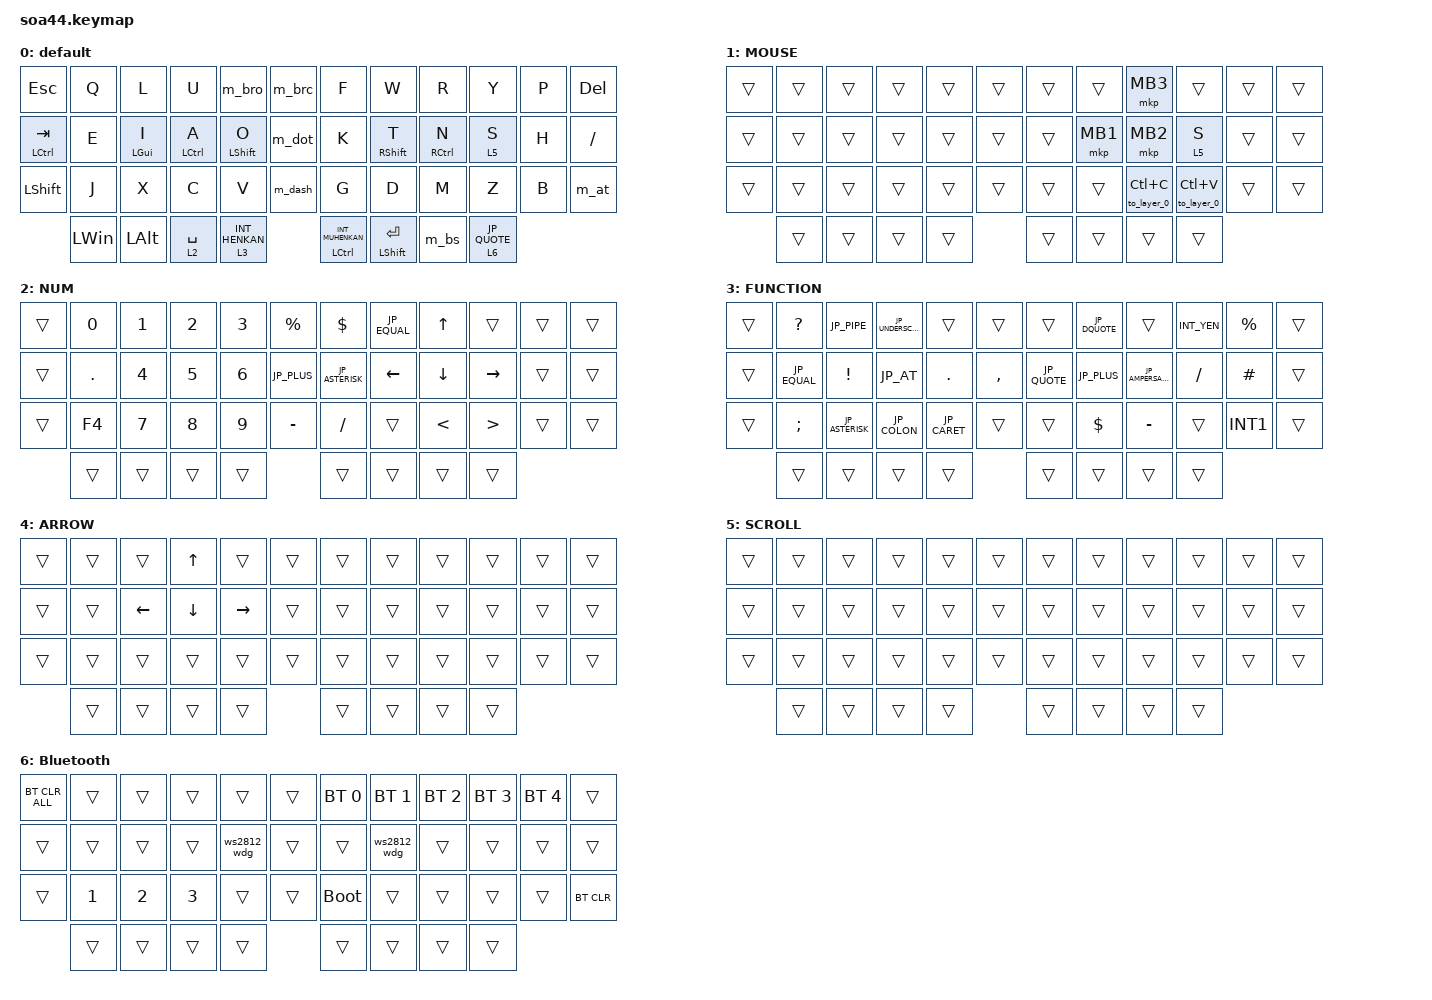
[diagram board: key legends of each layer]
#include <behaviors.dtsi>
#include <dt-bindings/zmk/bt.h>
#include <dt-bindings/zmk/keys.h>
#include <dt-bindings/zmk/pointing.h>
#include <input/processors.dtsi>
#include <behaviors/ws2812_widget.dtsi>

&mkp_input_listener {
    input-processors = <&zip_temp_layer 1 250>;
};
// OS設定を日本語キーボードのまま使用するための変換定義

#define JP_DQUOTE       AT                // "
#define JP_AMPERSAND    CARET             // &
#define JP_QUOTE        AMPERSAND         // '
#define JP_EQUAL        UNDER             // =
#define JP_CARET        EQUAL             // ^
#define JP_YEN          0x89              // ¥
#define JP_PLUS         COLON             // +
#define JP_TILDE        PLUS              // ~
#define JP_PIPE         LS(0x89)          // |
#define JP_AT           LEFT_BRACKET      // @
#define JP_COLON        SINGLE_QUOTE      // :
#define JP_ASTERISK     DOUBLE_QUOTES     // *
#define JP_BACKQUOTE    LEFT_BRACE        // `
#define JP_UNDERSCORE   LS(0x87)          // _
#define JP_LBRACKET     RIGHT_BRACKET     // [
#define JP_RBRACKET     BACKSLASH         // ]
#define JP_LPAREN       ASTERISK          // (
#define JP_RPAREN       LEFT_PARENTHESIS  // )
#define JP_LBRACE       RIGHT_BRACE       // {
#define JP_RBRACE       PIPE              // }
#define JP_KANA         LANGUAGE_1        // かな
#define JP_EISU         LANGUAGE_2        // 英数
#define JP_HANZEN       GRAVE             // 半角/全角

&mt {
    flavor = "balanced";
    quick-tap-ms = <0>;
};

/ {
    combos {
        compatible = "zmk,combos";

        shift_ctrl {
            bindings = <&kp LS(LCTRL)>;
            key-positions = <12 13>;
        };
    };

    macros {
        to_layer_0: to_layer_0 {
            compatible = "zmk,behavior-macro-one-param";
            #binding-cells = <1>;
            bindings = <&to 0 &macro_param_1to1 &kp MACRO_PLACEHOLDER>;
            label = "TO_LAYER_0";
        };
    };

    behaviors {
        lt_to_layer_0: lt_to_layer_0 {
            compatible = "zmk,behavior-hold-tap";
            label = "LAYER_TAP_TO_0";
            bindings = <&mo>, <&to_layer_0>;
            #binding-cells = <2>;
            tapping-term-ms = <200>;
        };
         // root：Shiftで分岐
        m_bro: m_bro {
            compatible = "zmk,behavior-mod-morph";
            #binding-cells = <0>;
            bindings = <&m_bron>, <&m_bros>;
            mods = <(MOD_LSFT|MOD_RSFT)>;
        };

        // 非Shiftルート：Ctrl判定
        m_bron: m_bron {
            compatible = "zmk,behavior-mod-morph";
            #binding-cells = <0>;
            bindings = <&kp JP_LPAREN>, <&kp JP_LBRACE>; // ( , {
            mods = <(MOD_LCTL|MOD_RCTL)>;
        };

        // Shiftルート：Ctrl判定
        m_bros: m_bros {
            compatible = "zmk,behavior-mod-morph";
            #binding-cells = <0>;
            bindings = <&kp JP_LBRACKET>, <&kp LT>; // [ , <
            mods = <(MOD_LCTL|MOD_RCTL)>;
        };
       // root：Shiftで分岐
        m_brc: m_brc {
            compatible = "zmk,behavior-mod-morph";
            #binding-cells = <0>;
            bindings = <&m_brcn>, <&m_brcs>;
            mods = <(MOD_LSFT|MOD_RSFT)>;
        };

        // 非Shiftルート：Ctrl判定
        m_brcn: m_brcn {
            compatible = "zmk,behavior-mod-morph";
            #binding-cells = <0>;
            bindings = <&kp JP_RPAREN>, <&kp JP_RBRACE>; // ) , }
            mods = <(MOD_LCTL|MOD_RCTL)>;
        };

        // Shiftルート：Ctrl判定
        m_brcs: m_brcs {
            compatible = "zmk,behavior-mod-morph";
            #binding-cells = <0>;
            bindings = <&kp JP_RBRACKET>, <&kp GT>; // ] , >
            mods = <(MOD_LCTL|MOD_RCTL)>;
        };
        m_dot: m_dot {
            compatible = "zmk,behavior-mod-morph";
            #binding-cells = <0>;
            bindings = <&kp PERIOD>, <&kp COMMA>; // . , ,
            mods = <(MOD_LSFT|MOD_RSFT)>;
        };
        m_dash: m_dash {
            compatible = "zmk,behavior-mod-morph";
            #binding-cells = <0>;
            bindings = <&kp MINUS>, <&kp JP_TILDE>; // - , ~
            mods = <(MOD_LSFT|MOD_RSFT)>;
        };
        m_at: m_at {
            compatible = "zmk,behavior-mod-morph";
            #binding-cells = <0>;
            bindings = <&kp JP_AT>, <&kp JP_UNDERSCORE>; // @ , _
            mods = <(MOD_LSFT|MOD_RSFT)>;
        };
        m_bs: m_bs {
            compatible = "zmk,behavior-mod-morph";
            #binding-cells = <0>;
            bindings = <&kp  BACKSPACE>, <&kp DEL>; 
            mods = <(MOD_LSFT|MOD_RSFT)>;
        };
        m_qw: m_qw {
            compatible = "zmk,behavior-mod-morph";
            #binding-cells = <0>;
            bindings = <&kp  JP_QUOTE>, <&kp JP_DQUOTE>; 
            mods = <(MOD_LSFT|MOD_RSFT)>;
        };
        ws2812_wdg: ws2812_wdg {
            compatible = "zmk,behavior-ws2812-widget";
            #binding-cells = <1>;
            label = "WS2812_WIDGET";
        };
    };

    keymap {
        compatible = "zmk,keymap";

        default {
            bindings = <
&kp ESCAPE      &kp Q         &kp L           &kp U                      &m_bro                     &m_brc                   &kp F                 &kp W              &kp R        &kp Y    &kp P          &kp DEL
&mt LCTRL TAB   &kp E         &mt LEFT_GUI I  &mt LCTRL A                &mt LEFT_SHIFT O           &m_dot                   &kp K                 &mt RIGHT_SHIFT T  &mt RCTRL N  &lt 5 S  &kp H          &kp SLASH
&kp LEFT_SHIFT  &kp J         &kp X           &kp C                      &kp V                      &m_dash                  &kp G                 &kp D              &kp M        &kp Z    &kp B          &m_at
                &kp LEFT_WIN  &kp LEFT_ALT    &lt 2 SPACE  &lt 3 INT_HENKAN               &mt LCTRL INT_MUHENKAN             &mt LEFT_SHIFT ENTER  &m_bs                           &lt 6 JP_QUOTE
            >;
        };

        MOUSE {
            bindings = <
&trans  &trans  &trans  &trans  &trans  &trans  &trans  &trans    &mkp MB3   &trans     &trans  &trans
&trans  &trans  &trans  &trans  &trans  &trans  &trans  &mkp MB1  &mkp MB2   &lt 5 S    &trans  &trans
&trans  &trans  &trans  &trans  &trans  &trans  &trans  &trans    &to_layer_0 LC(C)  &to_layer_0 LC(V)  &trans  &trans
        &trans  &trans  &trans  &trans  &trans  &trans  &trans                          &trans
            >;
        };

        NUM {
            bindings = <
&trans  &kp N0      &kp NUMBER_1  &kp NUMBER_2  &kp NUMBER_3  &kp PERCENT  &kp DOLLAR        &kp JP_EQUAL  &kp UP         &trans            &trans  &trans
&trans  &kp PERIOD  &kp NUMBER_4  &kp N5        &kp NUMBER_6  &kp JP_PLUS  &kp JP_ASTERISK   &kp LEFT   &kp DOWN       &kp RIGHT         &trans  &trans
&trans  &kp F4      &kp N7        &kp N8        &kp N9        &kp MINUS    &kp SLASH         &trans     &kp LESS_THAN  &kp GREATER_THAN  &trans  &trans
        &trans      &trans        &trans        &trans        &trans       &trans            &trans                                      &trans
            >;
        };

        FUNCTION {
            bindings = <
&trans  &kp QUESTION  &kp JP_PIPE      &kp JP_UNDERSCORE   &trans          &trans     &trans        &kp JP_DQUOTE      &trans            &kp INT_YEN  &kp PERCENT     &trans
&trans  &kp JP_EQUAL  &kp EXCLAMATION  &kp JP_AT           &kp PERIOD      &kp COMMA  &kp JP_QUOTE  &kp JP_PLUS        &kp JP_AMPERSAND  &kp SLASH    &kp HASH        &trans
&trans  &kp SEMI      &kp JP_ASTERISK  &kp JP_COLON        &kp JP_CARET    &trans     &trans        &kp DOLLAR         &kp MINUS         &trans       &kp INT1        &trans
        &trans        &trans           &trans              &trans          &trans     &trans        &trans                                         &trans
            >;
        };

        ARROW {
            bindings = <
&trans  &trans  &trans    &kp UP    &trans     &trans  &trans  &trans  &trans  &trans  &trans  &trans
&trans  &trans  &kp LEFT  &kp DOWN  &kp RIGHT  &trans  &trans  &trans  &trans  &trans  &trans  &trans
&trans  &trans  &trans    &trans    &trans     &trans  &trans  &trans  &trans  &trans  &trans  &trans
        &trans  &trans    &trans    &trans     &trans  &trans  &trans                  &trans
            >;
        };

        SCROLL {
            bindings = <
&trans  &trans  &trans  &trans  &trans  &trans  &trans  &trans  &trans  &trans  &trans  &trans
&trans  &trans  &trans  &trans  &trans  &trans  &trans  &trans  &trans  &trans  &trans  &trans
&trans  &trans  &trans  &trans  &trans  &trans  &trans  &trans  &trans  &trans  &trans  &trans
        &trans  &trans  &trans  &trans  &trans  &trans  &trans                  &trans
            >;
        };

        Bluetooth {
            bindings = <
&bt BT_CLR_ALL  &trans        &trans        &trans        &trans       &trans  &bt BT_SEL 0  &bt BT_SEL 1  &bt BT_SEL 2  &bt BT_SEL 3  &bt BT_SEL 4  &trans
&trans          &trans        &trans        &trans        &ws2812_wdg  &trans  &trans        &ws2812_wdg   &trans        &trans        &trans        &trans
&trans          &kp NUMBER_1  &kp NUMBER_2  &kp NUMBER_3  &trans       &trans  &bootloader   &trans        &trans        &trans        &trans        &bt BT_CLR
                &trans        &trans        &trans        &trans       &trans  &trans        &trans                                    &trans
            >;
        };
    };
};
